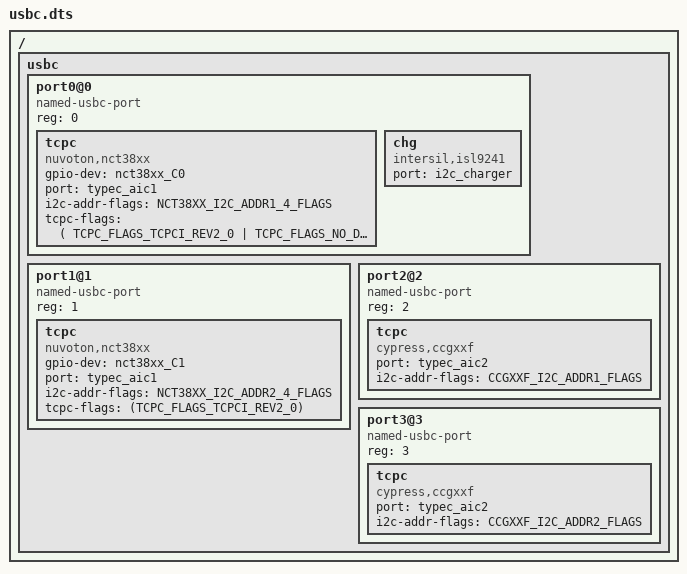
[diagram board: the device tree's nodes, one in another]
/* Copyright 2022 The Chromium OS Authors. All rights reserved.
 * Use of this source code is governed by a BSD-style license that can be
 * found in the LICENSE file.
 */

 #include <dt-bindings/usb_pd_tcpm.h>

/ {
	usbc {
		#address-cells = <1>;
		#size-cells = <0>;

		port0@0 {
			compatible = "named-usbc-port";
			reg = <0>;
			tcpc {
				compatible = "nuvoton,nct38xx";
				gpio-dev = <&nct38xx_C0>;
				port = <&typec_aic1>;
				i2c-addr-flags = "NCT38XX_I2C_ADDR1_4_FLAGS";
				tcpc-flags = <(
					TCPC_FLAGS_TCPCI_REV2_0 |
					TCPC_FLAGS_NO_DEBUG_ACC_CONTROL)>;
			};
			chg {
				compatible = "intersil,isl9241";
				status = "okay";
				port = <&i2c_charger>;
			};
		};

		port1@1 {
			compatible = "named-usbc-port";
			reg = <1>;
			tcpc {
				compatible = "nuvoton,nct38xx";
				gpio-dev = <&nct38xx_C1>;
				port = <&typec_aic1>;
				i2c-addr-flags = "NCT38XX_I2C_ADDR2_4_FLAGS";
				tcpc-flags = <(TCPC_FLAGS_TCPCI_REV2_0)>;
			};
		};

		port2@2 {
			compatible = "named-usbc-port";
			reg = <2>;
			tcpc {
				compatible = "cypress,ccgxxf";
				port = <&typec_aic2>;
				i2c-addr-flags = "CCGXXF_I2C_ADDR1_FLAGS";
			};
		};

		port3@3 {
			compatible = "named-usbc-port";
			reg = <3>;
			tcpc {
				compatible = "cypress,ccgxxf";
				port = <&typec_aic2>;
				i2c-addr-flags = "CCGXXF_I2C_ADDR2_FLAGS";
			};
		};
        };
};

